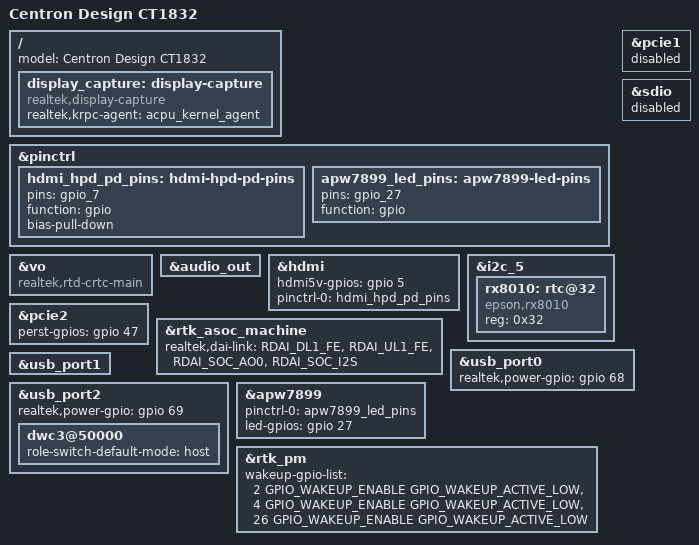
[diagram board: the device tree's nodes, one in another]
#include "rtd1619b-bleedingedge-2gb.dts"

&pinctrl {
	hdmi_hpd_pd_pins: hdmi-hpd-pd-pins {
		pins = "gpio_7";
		function = "gpio";
		bias-pull-down;
	};

	apw7899_led_pins: apw7899-led-pins {
		pins = "gpio_27";
		function = "gpio";
	};
};

/ {
	model = "Centron Design CT1832";

	display_capture: display-capture {
		compatible = "realtek,display-capture";
		realtek,krpc-agent = <&acpu_kernel_agent>;
		status = "okay";
	};
};

&vo {
	compatible = "realtek,rtd-crtc-main";
};

&audio_out {
	/delete-property/audio-gpios;
};

&hdmi {
	hdmi5v-gpios = <&gpio 5 GPIO_ACTIVE_HIGH>;
	pinctrl-names = "default";
	pinctrl-0 = <&hdmi_hpd_pd_pins>;
};

&i2c_5 {
	rx8010: rtc@32 {
		compatible = "epson,rx8010";
		reg = <0x32>;
	};
};

&pcie1 {
	/delete-property/perst-gpios;
	status = "disabled";
};

&pcie2 {
	perst-gpios = <&gpio 47 GPIO_ACTIVE_HIGH>;
};

&sdio {
	/delete-property/wifi-rst-gpios;
	status = "disabled";
};

&rtk_asoc_machine {
	/delete-property/pinctrl-0;
	realtek,dai-link = "RDAI_DL1_FE", "RDAI_UL1_FE", "RDAI_SOC_AO0", "RDAI_SOC_I2S";
};

&usb_port0 {
	realtek,power-gpio = <&gpio 68 GPIO_ACTIVE_HIGH>;
};

&usb_port1 {
	/delete-property/realtek,power-gpio;
};

&usb_port2 {
	realtek,power-gpio = <&gpio 69 GPIO_ACTIVE_HIGH>;
	dwc3@50000 {
		role-switch-default-mode = "host"; /* host, peripheral*/
	};
};

/delete-node/ &type_c;

&apw7899 {
	pinctrl-names = "default";
	pinctrl-0 = <&apw7899_led_pins>;

	/* gpio_27: LED output */
	led-gpios = <&gpio 27 GPIO_ACTIVE_HIGH>;
};

&rtk_pm {
	wakeup-gpio-list = <2  GPIO_WAKEUP_ENABLE GPIO_WAKEUP_ACTIVE_LOW>,
			   <4  GPIO_WAKEUP_ENABLE GPIO_WAKEUP_ACTIVE_LOW>,
			   <26 GPIO_WAKEUP_ENABLE GPIO_WAKEUP_ACTIVE_LOW>;
};
